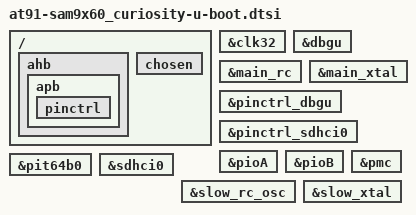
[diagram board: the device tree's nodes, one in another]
// SPDX-License-Identifier: (GPL-2.0+ OR MIT)
/*
 * at91-sam9x60_curiosity-u-boot.dtsi - Device Tree Include file for SAM9X60
 * CURIOSITY.
 *
 * Copyright (C) 2022 Microchip Technology Inc. and its subsidiaries
 *
 * Author: Durai Manickam KR <durai.manickamkr@microchip.com>
 */

/ {
	ahb {
		u-boot,dm-all;

		apb {
			u-boot,dm-all;

			pinctrl {
				u-boot,dm-all;
			};
		};
	};

	chosen {
		u-boot,dm-all;
	};
};

&clk32 {
	u-boot,dm-all;
};

&dbgu {
	u-boot,dm-all;
};

&main_rc {
	u-boot,dm-all;
};

&main_xtal {
	u-boot,dm-all;
};

&pinctrl_dbgu {
	u-boot,dm-all;
};

&pinctrl_sdhci0 {
	u-boot,dm-all;
};

&pioA {
	u-boot,dm-all;
};

&pioB {
	u-boot,dm-all;
};

&pit64b0 {
	u-boot,dm-all;
};

&pmc {
	u-boot,dm-all;
};

&sdhci0 {
	u-boot,dm-all;
};

&slow_rc_osc {
	u-boot,dm-all;
};

&slow_xtal {
	u-boot,dm-all;
};
